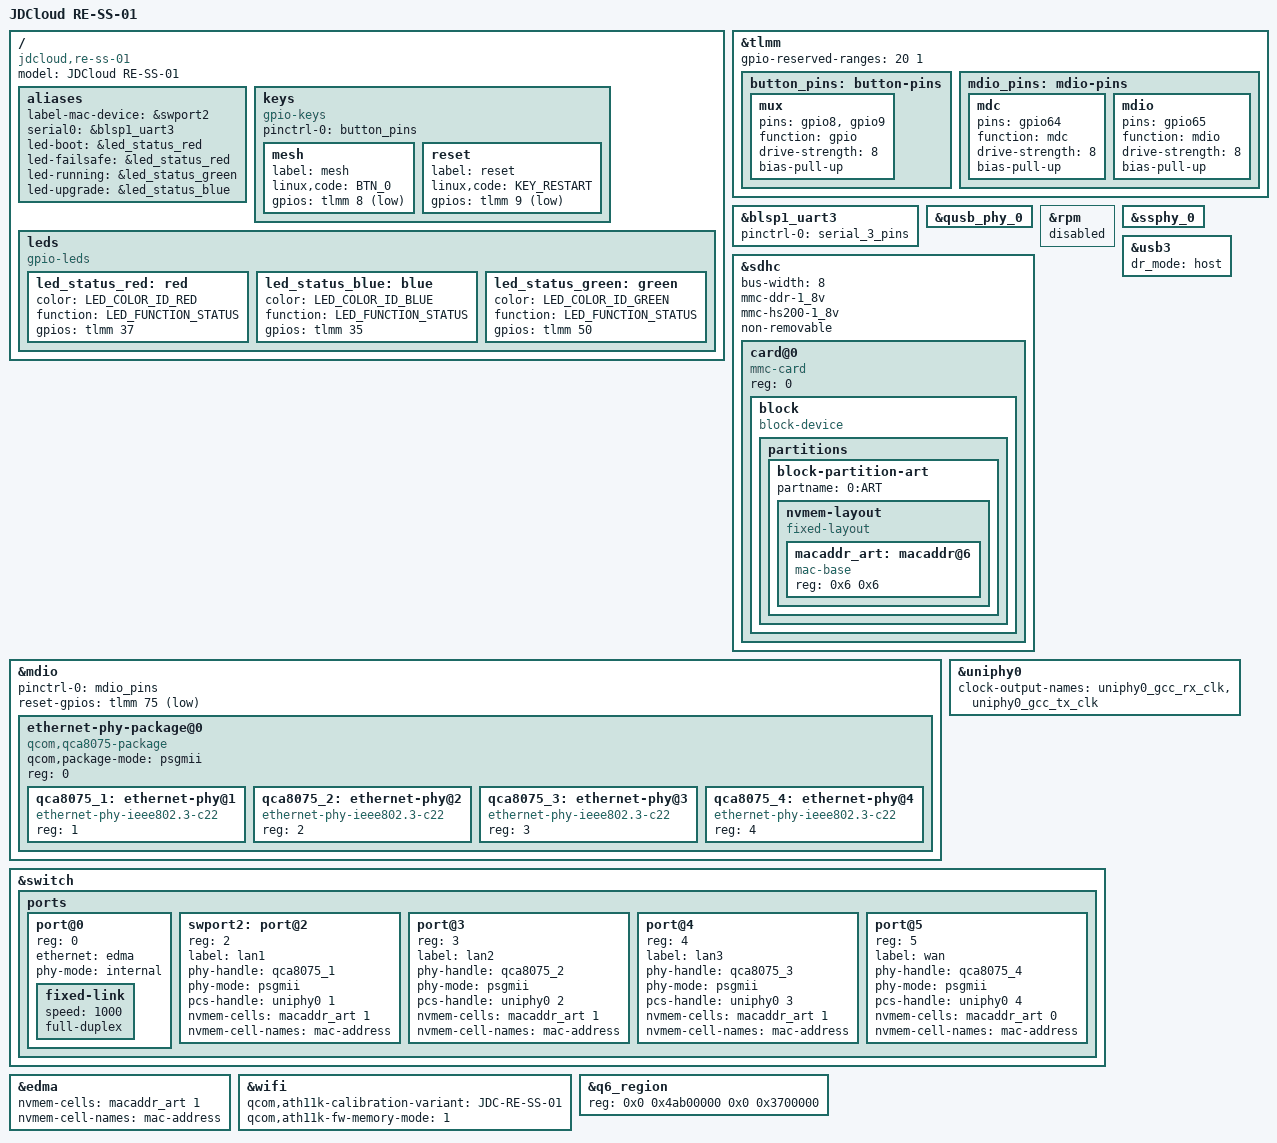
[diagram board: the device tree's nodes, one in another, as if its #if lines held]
// SPDX-License-Identifier: GPL-2.0-or-later OR MIT

/dts-v1/;

#include "ipq6018.dtsi"
#ifdef GWRT_SS01_NATIVE_NSS
#include "ipq6018-ess.dtsi"
#include "ipq6018-nss.dtsi"
#else
#include "ipq6018-ess-nss.dtsi"
#endif

#include <dt-bindings/gpio/gpio.h>
#include <dt-bindings/input/input.h>
#include <dt-bindings/leds/common.h>

/ {
	model = "JDCloud RE-SS-01";
	compatible = "jdcloud,re-ss-01", "qcom,ipq6018";

	aliases {
#ifdef GWRT_SS01_NATIVE_NSS
		label-mac-device = &swport2;
#else
		ethernet1 = &dp2;
		ethernet2 = &dp3;
		ethernet3 = &dp4;
		ethernet4 = &dp5;
		label-mac-device = &dp2;
#endif
		serial0 = &blsp1_uart3;
		led-boot = &led_status_red;
		led-failsafe = &led_status_red;
		led-running = &led_status_green;
		led-upgrade = &led_status_blue;
	};

	keys {
		compatible = "gpio-keys";
		pinctrl-0 = <&button_pins>;
		pinctrl-names = "default";

		mesh {
			label = "mesh";
			linux,code = <BTN_0>;
			gpios = <&tlmm 8 GPIO_ACTIVE_LOW>;
		};

		reset {
			label = "reset";
			linux,code = <KEY_RESTART>;
			gpios = <&tlmm 9 GPIO_ACTIVE_LOW>;
		};
	};

	leds {
		compatible = "gpio-leds";

		led_status_red: red {
			color = <LED_COLOR_ID_RED>;
			function = LED_FUNCTION_STATUS;
			gpios = <&tlmm 37 GPIO_ACTIVE_HIGH>;
		};

		led_status_blue: blue {
			color = <LED_COLOR_ID_BLUE>;
			function = LED_FUNCTION_STATUS;
			gpios = <&tlmm 35 GPIO_ACTIVE_HIGH>;
		};

		led_status_green: green {
			color = <LED_COLOR_ID_GREEN>;
			function = LED_FUNCTION_STATUS;
			gpios = <&tlmm 50 GPIO_ACTIVE_HIGH>;
		};
	};
};

&tlmm {
	gpio-reserved-ranges = <20 1>;

	button_pins: button-pins {
		mux {
			pins = "gpio8", "gpio9";
			function = "gpio";
			drive-strength = <8>;
			bias-pull-up;
		};
	};

	mdio_pins: mdio-pins {
		mdc {
			pins = "gpio64";
			function = "mdc";
			drive-strength = <8>;
			bias-pull-up;
		};

		mdio {
			pins = "gpio65";
			function = "mdio";
			drive-strength = <8>;
			bias-pull-up;
		};
	};
};

&blsp1_uart3 {
	pinctrl-0 = <&serial_3_pins>;
	pinctrl-names = "default";
	status = "okay";
};

&qusb_phy_0 {
	status = "okay";
};

&rpm {
	status = "disabled";
};

&sdhc {
	bus-width = <8>;
	mmc-ddr-1_8v;
	mmc-hs200-1_8v;
	non-removable;
	status = "okay";
#ifdef GWRT_SS01_NATIVE_NSS
	#address-cells = <1>;
	#size-cells = <0>;

	card@0 {
		compatible = "mmc-card";
		reg = <0>;

		block {
			compatible = "block-device";

			partitions {
				block-partition-art {
					partname = "0:ART";

					nvmem-layout {
						compatible = "fixed-layout";
						#address-cells = <1>;
						#size-cells = <1>;

						macaddr_art: macaddr@6 {
							compatible = "mac-base";
							reg = <0x6 0x6>;
							#nvmem-cell-cells = <1>;
						};
					};
				};
			};
		};
	};
#endif
};

&ssphy_0 {
	status = "okay";
};

&usb3 {
	status = "okay";
	dr_mode = "host";
};

&mdio {
	status = "okay";

	pinctrl-0 = <&mdio_pins>;
	pinctrl-names = "default";
	reset-gpios = <&tlmm 75 GPIO_ACTIVE_LOW>;

	ethernet-phy-package@0 {
		compatible = "qcom,qca8075-package";
#ifdef GWRT_SS01_NATIVE_NSS
		qcom,package-mode = "psgmii";
#endif
		#address-cells = <1>;
		#size-cells = <0>;
		reg = <0>;

		qca8075_1: ethernet-phy@1 {
			compatible = "ethernet-phy-ieee802.3-c22";
			reg = <1>;
		};

		qca8075_2: ethernet-phy@2 {
			compatible = "ethernet-phy-ieee802.3-c22";
			reg = <2>;
		};

		qca8075_3: ethernet-phy@3 {
			compatible = "ethernet-phy-ieee802.3-c22";
			reg = <3>;
		};

		qca8075_4: ethernet-phy@4 {
			compatible = "ethernet-phy-ieee802.3-c22";
			reg = <4>;
		};
	};
};

#ifdef GWRT_SS01_NATIVE_NSS
&uniphy0 {
	clock-output-names = "uniphy0_gcc_rx_clk", "uniphy0_gcc_tx_clk";
	status = "okay";
};

&switch {
	status = "okay";

	ports {
		#address-cells = <1>;
		#size-cells = <0>;

		port@0 {
			reg = <0>;
			ethernet = <&edma>;
			phy-mode = "internal";

			fixed-link {
				speed = <1000>;
				full-duplex;
			};
		};

		swport2: port@2 {
			reg = <2>;
			label = "lan1";
			phy-handle = <&qca8075_1>;
			phy-mode = "psgmii";
			pcs-handle = <&uniphy0 1>;
			nvmem-cells = <&macaddr_art 1>;
			nvmem-cell-names = "mac-address";
		};

		port@3 {
			reg = <3>;
			label = "lan2";
			phy-handle = <&qca8075_2>;
			phy-mode = "psgmii";
			pcs-handle = <&uniphy0 2>;
			nvmem-cells = <&macaddr_art 1>;
			nvmem-cell-names = "mac-address";
		};

		port@4 {
			reg = <4>;
			label = "lan3";
			phy-handle = <&qca8075_3>;
			phy-mode = "psgmii";
			pcs-handle = <&uniphy0 3>;
			nvmem-cells = <&macaddr_art 1>;
			nvmem-cell-names = "mac-address";
		};

		port@5 {
			reg = <5>;
			label = "wan";
			phy-handle = <&qca8075_4>;
			phy-mode = "psgmii";
			pcs-handle = <&uniphy0 4>;
			nvmem-cells = <&macaddr_art 0>;
			nvmem-cell-names = "mac-address";
		};
	};
};
#else
&switch {
	status = "okay";

	switch_lan_bmp = <(ESS_PORT2 | ESS_PORT3 | ESS_PORT4)>;
	switch_wan_bmp = <ESS_PORT5>;
	switch_mac_mode = <MAC_MODE_PSGMII>;

	qcom,port_phyinfo {
		port@2 {
			port_id = <2>;
			phy_address = <1>;
		};
		port@3 {
			port_id = <3>;
			phy_address = <2>;
		};
		port@4 {
			port_id = <4>;
			phy_address = <3>;
		};
		port@5 {
			port_id = <5>;
			phy_address = <4>;
		};
	};
};

&dp2 {
	status = "okay";
	phy-handle = <&qca8075_1>;
	label = "lan1";
};

&dp3 {
	status = "okay";
	phy-handle = <&qca8075_2>;
	label = "lan2";
};

&dp4 {
	status = "okay";
	phy-handle = <&qca8075_3>;
	label = "lan3";
};

&dp5 {
	status = "okay";
	phy-handle = <&qca8075_4>;
	label = "wan";
};
#endif

&edma {
	status = "okay";
#ifdef GWRT_SS01_NATIVE_NSS
	nvmem-cells = <&macaddr_art 1>;
	nvmem-cell-names = "mac-address";
#endif
};

&wifi {
	status = "okay";

	qcom,ath11k-calibration-variant = "JDC-RE-SS-01";
	qcom,ath11k-fw-memory-mode = <1>;
};

/* Keep the working DD-WRT AHB firmware reservation from the deployed DT. */
&q6_region {
	reg = <0x0 0x4ab00000 0x0 0x3700000>;
};
